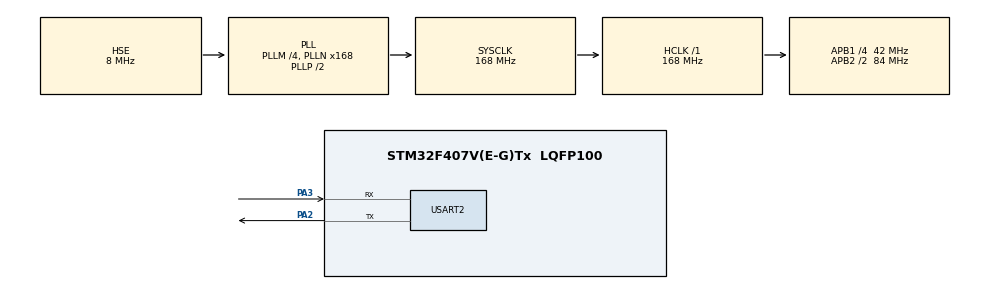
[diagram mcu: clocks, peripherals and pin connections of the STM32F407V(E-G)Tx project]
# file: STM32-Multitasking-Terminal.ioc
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FREERTOS.Tasks01=SensorTask,24,128,StartDefaultTask,Default,NULL,Dynamic,NULL,NULL;DisplayTask,16,128,StartDisplayTask,Default,NULL,Dynamic,NULL,NULL
Mcu.Family=STM32F4
Mcu.Name=STM32F407V(E-G)Tx
Mcu.Package=LQFP100
NVIC.PriorityGroup=NVIC_PRIORITYGROUP_4
NVIC.TIM6_DAC_IRQn=true\:15\:0\:false\:false\:true\:false\:false\:true\:true
NVIC.TimeBase=TIM6_DAC_IRQn
NVIC.TimeBaseIP=TIM6
PA13.Mode=Serial_Wire
PA13.Signal=SYS_JTMS-SWDIO
PA14.Mode=Serial_Wire
PA14.Signal=SYS_JTCK-SWCLK
PA2.Mode=Asynchronous
PA2.Signal=USART2_TX
PA3.Mode=Asynchronous
PA3.Signal=USART2_RX
PH0-OSC_IN.Mode=HSE-External-Oscillator
PH0-OSC_IN.Signal=RCC_OSC_IN
PH1-OSC_OUT.Mode=HSE-External-Oscillator
PH1-OSC_OUT.Signal=RCC_OSC_OUT
ProjectManager.HeapSize=0x200
ProjectManager.StackSize=0x400
ProjectManager.TargetToolchain=CMake
RCC.48MHZClocksFreq_Value=84000000
RCC.AHBFreq_Value=168000000
RCC.APB1CLKDivider=RCC_HCLK_DIV4
RCC.APB1Freq_Value=42000000
RCC.APB1TimFreq_Value=84000000
RCC.APB2CLKDivider=RCC_HCLK_DIV2
RCC.APB2Freq_Value=84000000
RCC.APB2TimFreq_Value=168000000
RCC.CortexFreq_Value=168000000
RCC.HCLKFreq_Value=168000000
RCC.HSE_VALUE=8000000
RCC.HSI_VALUE=16000000
RCC.LSE_VALUE=32768
RCC.PLLM=4
RCC.PLLN=168
RCC.PLLSourceVirtual=RCC_PLLSOURCE_HSE
RCC.SYSCLKFreq_VALUE=168000000
RCC.SYSCLKSource=RCC_SYSCLKSOURCE_PLLCLK
RCC.VCOOutputFreq_Value=336000000
USART2.VirtualMode=VM_ASYNC
VP_FREERTOS_VS_CMSIS_V2.Mode=CMSIS_V2
VP_SYS_VS_tim6.Mode=TIM6
board=custom

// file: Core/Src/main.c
/* USER CODE BEGIN Header */
/**
  ******************************************************************************
  * @file           : main.c
  * @brief          : Main program body
  ******************************************************************************
  * @attention
  *
  * Copyright (c) 2026 STMicroelectronics.
  * All rights reserved.
  *
  * This software is licensed under terms that can be found in the LICENSE file
  * in the root directory of this software component.
  * If no LICENSE file comes with this software, it is provided AS-IS.
  *
  ******************************************************************************
  */
/* USER CODE END Header */
#include "main.h"
#include "cmsis_os.h"
#include "usart.h"
#include "gpio.h"

/* USER CODE BEGIN Includes */

#include <stdio.h>

/* USER CODE END Includes */

/* USER CODE BEGIN PV */

uint16_t adc_buffer[1];

/* USER CODE END PV */

void SystemClock_Config(void);
void MX_FREERTOS_Init(void);

/* USER CODE BEGIN 0 */

extern UART_HandleTypeDef huart2;

int _write(int file, char *ptr, int len) {
  HAL_UART_Transmit(&huart2, (uint8_t*)ptr, len, HAL_MAX_DELAY);
  return len;
}

void Init_ADC_BareMetal(void) {
  //Port A (0)
  RCC->AHB1ENR |= (1 << 0);

  //ADC1 (8)
  RCC->APB2ENR |= (1 << 8);

  //Analog Mode (3 für Pin 0)
  GPIOA->MODER |= (3 << 0);

  //channel 0 (0 in bits 0-4)
  ADC1->SQR3 &= ~(0x1F << 0);

  //1 messung (0 in bits 20-23)
  ADC1->SQR1 &= ~(0xF << 20);

  //84 zyklen sampeln (100 in bits 0-2)
  ADC1->SMPR2 |= (4 << 0);

  //einschalten (bit 0)
  ADC1->CR2 |= (1 << 0);

  //8: dma, 9: kontinuierliche requests
  ADC1->CR2 |= (1 << 8) | (1 << 9);
}

void Init_DMA_BareMetal(void) {
  //dma2 (22)
  RCC->AHB1ENR |= (1 << 22);

  //deaktivieren für config
  DMA2_Stream0->CR &= ~(1 << 0);

  //hardware bestätigt deaktivierung
  while (DMA2_Stream0->CR & (1 << 0));

  //peripherie adresse festlegen
  DMA2_Stream0->PAR = (uint32_t)&ADC1->DR;

  //speicher adresse festlegen
  DMA2_Stream0->M0AR = (uint32_t)adc_buffer;

  //anzahl pakete pro register
  DMA2_Stream0->NDTR = 1;

  //control register reset (pheripheral to memory & chnannel 0 default)
  DMA2_Stream0->CR = 0;

  //perhiperal size: 16-bit ist 01 in bits 11-12
  DMA2_Stream0->CR |= (1 << 11);

  //memory size: 16-bit ist 01 in bits 13-14
  DMA2_Stream0->CR |= (1 << 13);

  //circiular mode: bit 8
  DMA2_Stream0->CR |= (1 << 8);

  //transfer complete interrupt enabe (bit 4)
  DMA2_Stream0->CR |= (1 << 4);

  //aktivieren (bit 0)
  DMA2_Stream0->CR |= (1 << 0);

  NVIC_SetPriority(DMA2_Stream0_IRQn, 5);

  NVIC_EnableIRQ(DMA2_Stream0_IRQn);
}

/* USER CODE END 0 */

int main(void)
{

  /* MCU Configuration--------------------------------------------------------*/

  /* Reset of all peripherals, Initializes the Flash interface and the Systick. */
  HAL_Init();

  /* Configure the system clock */
  SystemClock_Config();

  /* Initialize all configured peripherals */
  MX_GPIO_Init();
  MX_USART2_UART_Init();
  /* USER CODE BEGIN 2 */

  // SEGGER_SYSVIEW_Conf();
  // SEGGER_SYSVIEW_Start();

  Init_ADC_BareMetal();
  Init_DMA_BareMetal();

  /* USER CODE END 2 */

  /* Init scheduler */
  osKernelInitialize();  /* Call init function for freertos objects (in cmsis_os2.c) */
  MX_FREERTOS_Init();

  /* Start scheduler */
  osKernelStart();

  /* We should never get here as control is now taken by the scheduler */

  /* Infinite loop */
  while (1)
  {

  }
}

void SystemClock_Config(void)
{
  RCC_OscInitTypeDef RCC_OscInitStruct = {0};
  RCC_ClkInitTypeDef RCC_ClkInitStruct = {0};

  /** Configure the main internal regulator output voltage
  */
  __HAL_RCC_PWR_CLK_ENABLE();
  __HAL_PWR_VOLTAGESCALING_CONFIG(PWR_REGULATOR_VOLTAGE_SCALE1);

  /** Initializes the RCC Oscillators according to the specified parameters
  * in the RCC_OscInitTypeDef structure.
  */
  RCC_OscInitStruct.OscillatorType = RCC_OSCILLATORTYPE_HSE;
  RCC_OscInitStruct.HSEState = RCC_HSE_ON;
  RCC_OscInitStruct.PLL.PLLState = RCC_PLL_ON;
  RCC_OscInitStruct.PLL.PLLSource = RCC_PLLSOURCE_HSE;
  RCC_OscInitStruct.PLL.PLLM = 4;
  RCC_OscInitStruct.PLL.PLLN = 168;
  RCC_OscInitStruct.PLL.PLLP = RCC_PLLP_DIV2;
  RCC_OscInitStruct.PLL.PLLQ = 4;
  if (HAL_RCC_OscConfig(&RCC_OscInitStruct) != HAL_OK)
  {
    Error_Handler();
  }

  /** Initializes the CPU, AHB and APB buses clocks
  */
  RCC_ClkInitStruct.ClockType = RCC_CLOCKTYPE_HCLK|RCC_CLOCKTYPE_SYSCLK
                              |RCC_CLOCKTYPE_PCLK1|RCC_CLOCKTYPE_PCLK2;
  RCC_ClkInitStruct.SYSCLKSource = RCC_SYSCLKSOURCE_PLLCLK;
  RCC_ClkInitStruct.AHBCLKDivider = RCC_SYSCLK_DIV1;
  RCC_ClkInitStruct.APB1CLKDivider = RCC_HCLK_DIV4;
  RCC_ClkInitStruct.APB2CLKDivider = RCC_HCLK_DIV2;

  if (HAL_RCC_ClockConfig(&RCC_ClkInitStruct, FLASH_LATENCY_5) != HAL_OK)
  {
    Error_Handler();
  }
}

/* USER CODE BEGIN 4 */

void DMA2_Stream0_IRQHandler(void) {

    //interrupt von channel 0 transfer complete prüfen
    if (DMA2->LISR & (1 << 5)) {

        //interrupt clear
        DMA2->LIFCR = (1 << 5);

        //sensor task flag senden
        osThreadFlagsSet(SensorTaskHandle, 0x01);
    }
}

/* USER CODE END 4 */

void HAL_TIM_PeriodElapsedCallback(TIM_HandleTypeDef *htim)
{
  if (htim->Instance == TIM6)
  {
    HAL_IncTick();
  }
}

void Error_Handler(void)
{
  __disable_irq();
  while (1)
  {
  }
}

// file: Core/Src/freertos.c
/* USER CODE BEGIN Header */
/**
  ******************************************************************************
  * File Name          : freertos.c
  * Description        : Code for freertos applications
  ******************************************************************************
  * @attention
  *
  * Copyright (c) 2026 STMicroelectronics.
  * All rights reserved.
  *
  * This software is licensed under terms that can be found in the LICENSE file
  * in the root directory of this software component.
  * If no LICENSE file comes with this software, it is provided AS-IS.
  *
  ******************************************************************************
  */
/* USER CODE END Header */

#include "FreeRTOS.h"
#include "task.h"
#include "main.h"
#include "cmsis_os.h"

/* USER CODE BEGIN Includes */

#include <stdio.h>

/* USER CODE END Includes */

/* Definitions for SensorTask */
osThreadId_t SensorTaskHandle;
const osThreadAttr_t SensorTask_attributes = {
  .name = "SensorTask",
  .stack_size = 256 * 4,
  .priority = (osPriority_t) osPriorityNormal,
};
/* Definitions for DisplayTask */
osThreadId_t DisplayTaskHandle;
const osThreadAttr_t DisplayTask_attributes = {
  .name = "DisplayTask",
  .stack_size = 256 * 4,
  .priority = (osPriority_t) osPriorityBelowNormal,
};

void StartDefaultTask(void *argument);
void StartDisplayTask(void *argument);

void MX_FREERTOS_Init(void); /* (MISRA C 2004 rule 8.1) */

void MX_FREERTOS_Init(void) {

  /* Create the thread(s) */
  /* creation of SensorTask */
  SensorTaskHandle = osThreadNew(StartDefaultTask, NULL, &SensorTask_attributes);

  /* creation of DisplayTask */
  DisplayTaskHandle = osThreadNew(StartDisplayTask, NULL, &DisplayTask_attributes);

}

void StartDefaultTask(void *argument)
{
  /* USER CODE BEGIN StartDefaultTask */
  /* Infinite loop */
  for(;;)
  {
    ADC1->CR2 |= (1 << 30); //start

    //auf flag warten
    osThreadFlagsWait(0x01, osFlagsWaitAny, osWaitForever);

    printf("[Bare-Metal] Poti-Wert: %u\r\n", adc_buffer[0]);

    osDelay(500);
  }
  /* USER CODE END StartDefaultTask */
}

void StartDisplayTask(void *argument)
{
  /* USER CODE BEGIN StartDisplayTask */
  /* Infinite loop */
  for(;;)
  {
    printf("[Display] Priorität BelowNormal\r\n");

    osDelay(1000);
  }
  /* USER CODE END StartDisplayTask */
}
